AUTOSAR XML (schema 4-2-2)
package /ComponentTypes
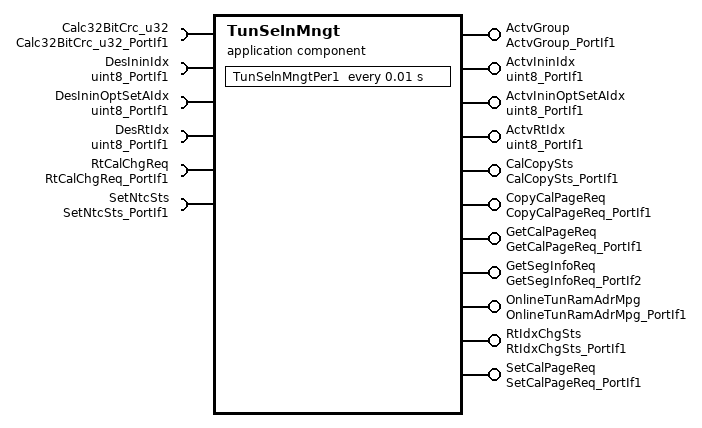
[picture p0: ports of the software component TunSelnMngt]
  application sw component type TunSelnMngt
    11 x provide port:
      ActvGroup: nonqueued-sender-com-spec{data-element=Val, init-value=0}, provided-interface=ActvGroup_PortIf1
      ActvIninIdx: nonqueued-sender-com-spec{data-element=Val, init-value=0}, provided-interface=uint8_PortIf1
      ActvIninOptSetAIdx: nonqueued-sender-com-spec{data-element=Val, init-value=0}, provided-interface=uint8_PortIf1
      ActvRtIdx: nonqueued-sender-com-spec{data-element=Val, init-value=0}, provided-interface=uint8_PortIf1
      CalCopySts: nonqueued-sender-com-spec{data-element=Val, init-value=0}, provided-interface=CalCopySts_PortIf1
      CopyCalPageReq: server-com-spec{operation=Oper, queue-length=1}, provided-interface=CopyCalPageReq_PortIf1
      GetCalPageReq: server-com-spec{operation=Oper, queue-length=1}, provided-interface=GetCalPageReq_PortIf1
      GetSegInfoReq: server-com-spec{operation=Oper, queue-length=1}, provided-interface=GetSegInfoReq_PortIf2
      OnlineTunRamAdrMpg: server-com-spec{operation=Oper, queue-length=1}, provided-interface=OnlineTunRamAdrMpg_PortIf1
      RtIdxChgSts: nonqueued-sender-com-spec{data-element=Val, init-value=0}, provided-interface=RtIdxChgSts_PortIf1
      SetCalPageReq: server-com-spec{operation=Oper, queue-length=1}, provided-interface=SetCalPageReq_PortIf1
    6 x require port:
      Calc32BitCrc_u32: client-com-spec=Oper, required-interface=Calc32BitCrc_u32_PortIf1
      DesIninIdx: nonqueued-receiver-com-spec{data-element=Val, filter=data-filter-type=ALWAYS, init-value=0}, required-interface=uint8_PortIf1
      DesIninOptSetAIdx: nonqueued-receiver-com-spec{data-element=Val, filter=data-filter-type=ALWAYS, init-value=0}, required-interface=uint8_PortIf1
      DesRtIdx: nonqueued-receiver-com-spec{data-element=Val, filter=data-filter-type=ALWAYS, init-value=0}, required-interface=uint8_PortIf1
      RtCalChgReq: client-com-spec=Oper, required-interface=RtCalChgReq_PortIf1
      SetNtcSts: client-com-spec=Oper, required-interface=SetNtcSts_PortIf1
    behavior TunSelnMngt_InternalBehavior
      exclusive area TunSelnMngtIntDataProtnExclsvArea
      ar-typed-per-instance-memorys:
        7 x data, all with sw-calibration-access=READ-ONLY:
          OnlineCalSts: type=OnlineCalStsRec2
          PrevActvIninIdx: type=uint8
          PrevActvIninOptSetAIdx: type=uint8
          PrevActvRtIdx: type=uint8
          PrevRamPageAcs: type=uint8
          PrevRtIdxChgSts: type=RtIdxChgSts1
          RamTblSwt: type=uint8
      5 x operation invoked event:
        OIT_CopyCalPageReq_Oper_CopyCalPageReq_Oper: start-on-event=CopyCalPageReq_Oper, operation=CopyCalPageReq.Oper
        OIT_GetCalPageReq_Oper_GetCalPageReq_Oper: start-on-event=GetCalPageReq_Oper, operation=GetCalPageReq.Oper
        OIT_GetSegInfoReq_Oper_GetSegInfoReq_Oper: start-on-event=GetSegInfoReq_Oper, operation=GetSegInfoReq.Oper
        OIT_OnlineTunRamAdrMpg_Oper_OnlineTunRamAdrMpg_Oper: start-on-event=OnlineTunRamAdrMpg_Oper, operation=OnlineTunRamAdrMpg.Oper
        OIT_SetCalPageReq_Oper_SetCalPageReq_Oper: start-on-event=SetCalPageReq_Oper, operation=SetCalPageReq.Oper
      init event TunSelnMngtInit1_InitEvent: start-on-event=TunSelnMngtInit1
      timing event TMT_TunSelnMngtPer1: start-on-event=TunSelnMngtPer1, period=0.01
      port-api-options:
        enable-take-address=false, error-handling=NO-TRANSFORMER-ERROR-HANDLING, indirect-api=false, port=ActvIninOptSetAIdx
        enable-take-address=false, error-handling=NO-TRANSFORMER-ERROR-HANDLING, indirect-api=false, port=DesIninOptSetAIdx
        enable-take-address=false, error-handling=NO-TRANSFORMER-ERROR-HANDLING, indirect-api=false, port=RtIdxChgSts
      7 x runnable:
        CopyCalPageReq_Oper: can-enter-exclusive-area=TunSelnMngtIntDataProtnExclsvArea
        GetCalPageReq_Oper
        GetSegInfoReq_Oper
        OnlineTunRamAdrMpg_Oper
        SetCalPageReq_Oper: can-enter-exclusive-area=TunSelnMngtIntDataProtnExclsvArea
        TunSelnMngtInit1
          data-receive-point-by-arguments:
            access REC_DesIninIdx_Val: accessed-variable=DesIninIdx.Val
            access REC_DesIninOptSetAIdx_Val: accessed-variable=DesIninOptSetAIdx.Val
            access REC_DesRtIdx_Val: accessed-variable=DesRtIdx.Val
          data-send-points:
            6 x access:
              SEND_ActvGroup_Val: accessed-variable=ActvGroup.Val
              SEND_ActvIninIdx_Val: accessed-variable=ActvIninIdx.Val
              SEND_ActvIninOptSetAIdx_Val: accessed-variable=ActvIninOptSetAIdx.Val
              SEND_ActvRtIdx_Val: accessed-variable=ActvRtIdx.Val
              SEND_CalCopySts_Val: accessed-variable=CalCopySts.Val
              SEND_RtIdxChgSts_Val: accessed-variable=RtIdxChgSts.Val
          sync call SC_Calc32BitCrc_u32_Oper: operation=Calc32BitCrc_u32.Oper, timeout=0
          sync call SC_SetNtcSts_Oper: operation=SetNtcSts.Oper, timeout=0
        TunSelnMngtPer1
          data-receive-point-by-arguments:
            access REC_DesRtIdx_Val: accessed-variable=DesRtIdx.Val
          data-send-points:
            4 x access:
              SEND_ActvGroup_Val: accessed-variable=ActvGroup.Val
              SEND_ActvRtIdx_Val: accessed-variable=ActvRtIdx.Val
              SEND_CalCopySts_Val: accessed-variable=CalCopySts.Val
              SEND_RtIdxChgSts_Val: accessed-variable=RtIdxChgSts.Val
          sync call SC_Calc32BitCrc_u32_Oper: operation=Calc32BitCrc_u32.Oper, timeout=0
          sync call SC_RtCalChgReq_Oper: operation=RtCalChgReq.Oper, timeout=0
          sync call SC_SetNtcSts_Oper: operation=SetNtcSts.Oper, timeout=0
  swc implementation TunSelnMngt_Implementation: behavior=TunSelnMngt_InternalBehavior
    code-descriptors:
      code Default: artifact-descriptors=autosar-engineering-object={short-label=Default, category=SWSRC}
